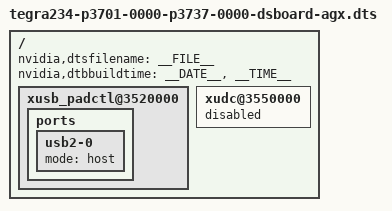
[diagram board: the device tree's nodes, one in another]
/*
 * Top level DTS file for CVM:P3701-0000 and CVB:DSBOARD-AGX.
 *
 * Copyright (c) 2021-2022, NVIDIA CORPORATION.  All rights reserved.
 *
 * This program is free software; you can redistribute it and/or modify
 * it under the terms of the GNU General Public License as published by
 * the Free Software Foundation; version 2 of the License.
 *
 * This program is distributed in the hope that it will be useful, but WITHOUT
 * ANY WARRANTY; without even the implied warranty of MERCHANTABILITY or
 * FITNESS FOR A PARTICULAR PURPOSE.  See the GNU General Public License for
 * more details.
 */

/dts-v1/;

#include "tegra234-p3701-0000-p3737-0000-dsboard-agx-base.dts"

/ {
	nvidia,dtsfilename = __FILE__;
	nvidia,dtbbuildtime = __DATE__, __TIME__;

	xusb_padctl@3520000 {
		ports {
			usb2-0 {
				mode = "host";
				/delete-property/ usb-role-switch;
				/delete-node/ connector;
			};
		};
	};

	xudc@3550000 {
		status = "disabled";
	};
};
